AUTOSAR XML (schema 4-0-3)
package /ADPR_Code_pkg/ADPR_Code_swc
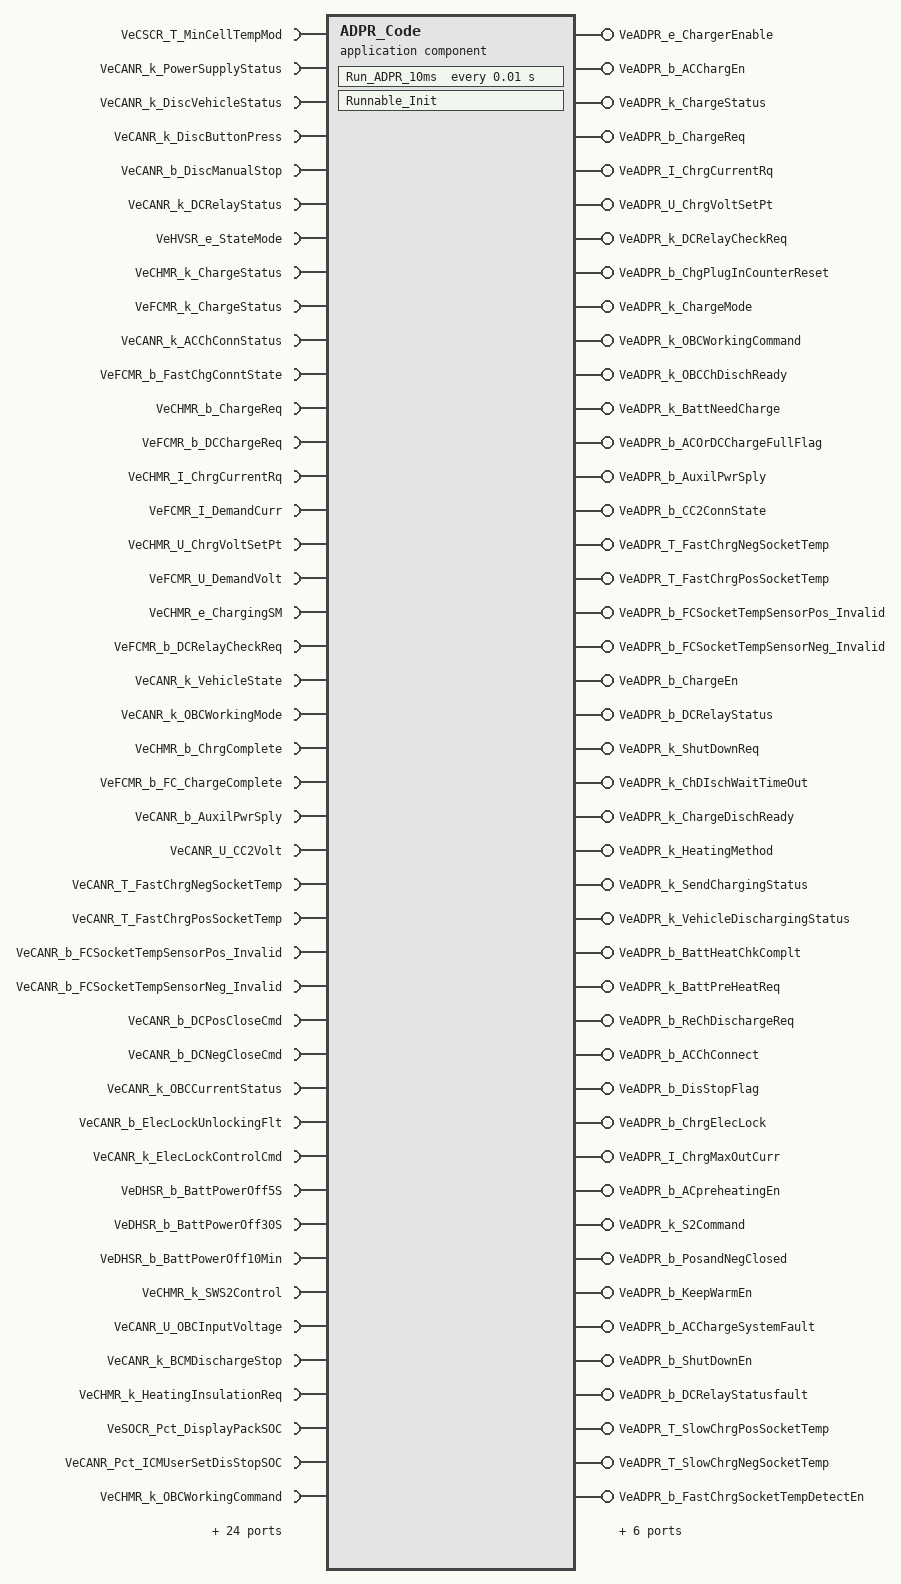
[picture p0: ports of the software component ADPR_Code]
  application sw component type ADPR_Code
    67 x require port:
      VeCSCR_T_MinCellTempMod: nonqueued-receiver-com-spec{data-element=VeCSCR_T_MinCellTempMod, init-value=0}, required-interface=VeCSCR_T_MinCellTempMod
      VeCANR_k_PowerSupplyStatus: nonqueued-receiver-com-spec{data-element=VeCANR_k_PowerSupplyStatus, init-value=0}, required-interface=VeCANR_k_PowerSupplyStatus
      VeCANR_k_DiscVehicleStatus: nonqueued-receiver-com-spec{data-element=VeCANR_k_DiscVehicleStatus, init-value=0}, required-interface=VeCANR_k_DiscVehicleStatus
      VeCANR_k_DiscButtonPress: nonqueued-receiver-com-spec{data-element=VeCANR_k_DiscButtonPress, init-value=0}, required-interface=VeCANR_k_DiscButtonPress
      VeCANR_b_DiscManualStop: nonqueued-receiver-com-spec{data-element=VeCANR_b_DiscManualStop, init-value=0}, required-interface=VeCANR_b_DiscManualStop
      VeCANR_k_DCRelayStatus: nonqueued-receiver-com-spec{data-element=VeCANR_k_DCRelayStatus, init-value=0}, required-interface=VeCANR_k_DCRelayStatus
      VeHVSR_e_StateMode: nonqueued-receiver-com-spec{data-element=VeHVSR_e_StateMode, init-value=CeHVSR_e_StateModeReserved}, required-interface=VeHVSR_e_StateMode
      VeCHMR_k_ChargeStatus: nonqueued-receiver-com-spec{data-element=VeCHMR_k_ChargeStatus, init-value=0}, required-interface=VeCHMR_k_ChargeStatus
      VeFCMR_k_ChargeStatus: nonqueued-receiver-com-spec{data-element=VeFCMR_k_ChargeStatus, init-value=0}, required-interface=VeFCMR_k_ChargeStatus
      VeCANR_k_ACChConnStatus: nonqueued-receiver-com-spec{data-element=VeCANR_k_ACChConnStatus, init-value=0}, required-interface=VeCANR_k_ACChConnStatus
      VeFCMR_b_FastChgConntState: nonqueued-receiver-com-spec{data-element=VeFCMR_b_FastChgConntState, init-value=0}, required-interface=VeFCMR_b_FastChgConntState
      VeCHMR_b_ChargeReq: nonqueued-receiver-com-spec{data-element=VeCHMR_b_ChargeReq, init-value=0}, required-interface=VeCHMR_b_ChargeReq
      VeFCMR_b_DCChargeReq: nonqueued-receiver-com-spec{data-element=VeFCMR_b_DCChargeReq, init-value=0}, required-interface=VeFCMR_b_DCChargeReq
      VeCHMR_I_ChrgCurrentRq: nonqueued-receiver-com-spec{data-element=VeCHMR_I_ChrgCurrentRq, init-value=0}, required-interface=VeCHMR_I_ChrgCurrentRq
      VeFCMR_I_DemandCurr: nonqueued-receiver-com-spec{data-element=VeFCMR_I_DemandCurr, init-value=0}, required-interface=VeFCMR_I_DemandCurr
      VeCHMR_U_ChrgVoltSetPt: nonqueued-receiver-com-spec{data-element=VeCHMR_U_ChrgVoltSetPt, init-value=0}, required-interface=VeCHMR_U_ChrgVoltSetPt
      VeFCMR_U_DemandVolt: nonqueued-receiver-com-spec{data-element=VeFCMR_U_DemandVolt, init-value=0}, required-interface=VeFCMR_U_DemandVolt
      VeCHMR_e_ChargingSM: nonqueued-receiver-com-spec{data-element=VeCHMR_e_ChargingSM, init-value=CeCHMR_e_ChargingSM_Off}, required-interface=VeCHMR_e_ChargingSM
      VeFCMR_b_DCRelayCheckReq: nonqueued-receiver-com-spec{data-element=VeFCMR_b_DCRelayCheckReq, init-value=0}, required-interface=VeFCMR_b_DCRelayCheckReq
      VeCANR_k_VehicleState: nonqueued-receiver-com-spec{data-element=VeCANR_k_VehicleState, init-value=0}, required-interface=VeCANR_k_VehicleState
      VeCANR_k_OBCWorkingMode: nonqueued-receiver-com-spec{data-element=VeCANR_k_OBCWorkingMode, init-value=0}, required-interface=VeCANR_k_OBCWorkingMode
      VeCHMR_b_ChrgComplete: nonqueued-receiver-com-spec{data-element=VeCHMR_b_ChrgComplete, init-value=0}, required-interface=VeCHMR_b_ChrgComplete
      VeFCMR_b_FC_ChargeComplete: nonqueued-receiver-com-spec{data-element=VeFCMR_b_FC_ChargeComplete, init-value=0}, required-interface=VeFCMR_b_FC_ChargeComplete
      VeCANR_b_AuxilPwrSply: nonqueued-receiver-com-spec{data-element=VeCANR_b_AuxilPwrSply, init-value=0}, required-interface=VeCANR_b_AuxilPwrSply
      VeCANR_U_CC2Volt: nonqueued-receiver-com-spec{data-element=VeCANR_U_CC2Volt, init-value=0}, required-interface=VeCANR_U_CC2Volt
      VeCANR_T_FastChrgNegSocketTemp: nonqueued-receiver-com-spec{data-element=VeCANR_T_FastChrgNegSocketTemp, init-value=0}, required-interface=VeCANR_T_FastChrgNegSocketTemp
      VeCANR_T_FastChrgPosSocketTemp: nonqueued-receiver-com-spec{data-element=VeCANR_T_FastChrgPosSocketTemp, init-value=0}, required-interface=VeCANR_T_FastChrgPosSocketTemp
      VeCANR_b_FCSocketTempSensorPos_Invalid: nonqueued-receiver-com-spec{data-element=VeCANR_b_FCSocketTempSensorPos_Invalid, init-value=0}, required-interface=VeCANR_b_FCSocketTempSensorPos_Invalid
      VeCANR_b_FCSocketTempSensorNeg_Invalid: nonqueued-receiver-com-spec{data-element=VeCANR_b_FCSocketTempSensorNeg_Invalid, init-value=0}, required-interface=VeCANR_b_FCSocketTempSensorNeg_Invalid
      VeCANR_b_DCPosCloseCmd: nonqueued-receiver-com-spec{data-element=VeCANR_b_DCPosCloseCmd, init-value=0}, required-interface=VeCANR_b_DCPosCloseCmd
      VeCANR_b_DCNegCloseCmd: nonqueued-receiver-com-spec{data-element=VeCANR_b_DCNegCloseCmd, init-value=0}, required-interface=VeCANR_b_DCNegCloseCmd
      VeCANR_k_OBCCurrentStatus: nonqueued-receiver-com-spec{data-element=VeCANR_k_OBCCurrentStatus, init-value=0}, required-interface=VeCANR_k_OBCCurrentStatus
      VeCANR_b_ElecLockUnlockingFlt: nonqueued-receiver-com-spec{data-element=VeCANR_b_ElecLockUnlockingFlt, init-value=0}, required-interface=VeCANR_b_ElecLockUnlockingFlt
      VeCANR_k_ElecLockControlCmd: nonqueued-receiver-com-spec{data-element=VeCANR_k_ElecLockControlCmd, init-value=0}, required-interface=VeCANR_k_ElecLockControlCmd
      VeDHSR_b_BattPowerOff5S: nonqueued-receiver-com-spec{data-element=VeDHSR_b_BattPowerOff5S, init-value=0}, required-interface=VeDHSR_b_BattPowerOff5S
      VeDHSR_b_BattPowerOff30S: nonqueued-receiver-com-spec{data-element=VeDHSR_b_BattPowerOff30S, init-value=0}, required-interface=VeDHSR_b_BattPowerOff30S
      VeDHSR_b_BattPowerOff10Min: nonqueued-receiver-com-spec{data-element=VeDHSR_b_BattPowerOff10Min, init-value=0}, required-interface=VeDHSR_b_BattPowerOff10Min
      VeCHMR_k_SWS2Control: nonqueued-receiver-com-spec{data-element=VeCHMR_k_SWS2Control, init-value=0}, required-interface=VeCHMR_k_SWS2Control
      VeCANR_U_OBCInputVoltage: nonqueued-receiver-com-spec{data-element=VeCANR_U_OBCInputVoltage, init-value=0}, required-interface=VeCANR_U_OBCInputVoltage
      VeCANR_k_BCMDischargeStop: nonqueued-receiver-com-spec{data-element=VeCANR_k_BCMDischargeStop, init-value=0}, required-interface=VeCANR_k_BCMDischargeStop
      VeCHMR_k_HeatingInsulationReq: nonqueued-receiver-com-spec{data-element=VeCHMR_k_HeatingInsulationReq, init-value=0}, required-interface=VeCHMR_k_HeatingInsulationReq
      VeSOCR_Pct_DisplayPackSOC: nonqueued-receiver-com-spec{data-element=VeSOCR_Pct_DisplayPackSOC, init-value=0}, required-interface=VeSOCR_Pct_DisplayPackSOC
      VeCANR_Pct_ICMUserSetDisStopSOC: nonqueued-receiver-com-spec{data-element=VeCANR_Pct_ICMUserSetDisStopSOC, init-value=0}, required-interface=VeCANR_Pct_ICMUserSetDisStopSOC
      VeCHMR_k_OBCWorkingCommand: nonqueued-receiver-com-spec{data-element=VeCHMR_k_OBCWorkingCommand, init-value=0}, required-interface=VeCHMR_k_OBCWorkingCommand
      VeCANR_k_VCUVehicleModel: nonqueued-receiver-com-spec{data-element=VeCANR_k_VCUVehicleModel, init-value=0}, required-interface=VeCANR_k_VCUVehicleModel
      VeCHMR_b_HeatingInsulationReqcomplt: nonqueued-receiver-com-spec{data-element=VeCHMR_b_HeatingInsulationReqcomplt, init-value=0}, required-interface=VeCHMR_b_HeatingInsulationReqcomplt
      VeFCMR_b_DCPreHeatChkCmplt: nonqueued-receiver-com-spec{data-element=VeFCMR_b_DCPreHeatChkCmplt, init-value=0}, required-interface=VeFCMR_b_DCPreHeatChkCmplt
      VeFCMR_b_DCPreHeatReq: nonqueued-receiver-com-spec{data-element=VeFCMR_b_DCPreHeatReq, init-value=0}, required-interface=VeFCMR_b_DCPreHeatReq
      VeCHMR_b_ReChargeStatus: nonqueued-receiver-com-spec{data-element=VeCHMR_b_ReChargeStatus, init-value=0}, required-interface=VeCHMR_b_ReChargeStatus
      VeCANR_b_ACAwake: nonqueued-receiver-com-spec{data-element=VeCANR_b_ACAwake, init-value=0}, required-interface=VeCANR_b_ACAwake
      VeCANR_e_ChrgElecLock: nonqueued-receiver-com-spec{data-element=VeCANR_e_ChrgElecLock, init-value=CeCHMR_e_ChrgElecLockUnlock}, required-interface=VeCANR_e_ChrgElecLock
      VeCSCR_U_PackVoltage_out: nonqueued-receiver-com-spec{data-element=VeCSCR_U_PackVoltage_out, init-value=0}, required-interface=VeCSCR_U_PackVoltage_out
      VeFCMR_b_DC_PowerDownReq: nonqueued-receiver-com-spec{data-element=VeFCMR_b_DC_PowerDownReq, init-value=0}, required-interface=VeFCMR_b_DC_PowerDownReq
      VeFCMR_e_ChrgOffBoardSt: nonqueued-receiver-com-spec{data-element=VeFCMR_e_ChrgOffBoardSt, init-value=CeFCMR_e_ChrgOffBoard_Init}, required-interface=VeFCMR_e_ChrgOffBoardSt
      VeCANR_b_OnWakeUp: nonqueued-receiver-com-spec{data-element=VeCANR_b_OnWakeUp, init-value=0}, required-interface=VeCANR_b_OnWakeUp
      VeCANR_b_GridBreakeFlag: nonqueued-receiver-com-spec{data-element=VeCANR_b_GridBreakeFlag, init-value=0}, required-interface=VeCANR_b_GridBreakeFlag
      VeFCMR_k_KeepWarmReqStatus: nonqueued-receiver-com-spec{data-element=VeFCMR_k_KeepWarmReqStatus, init-value=0}, required-interface=VeFCMR_k_KeepWarmReqStatus
      VeTHMR_k_BMSToEHUInslationReq: nonqueued-receiver-com-spec{data-element=VeTHMR_k_BMSToEHUInslationReq, init-value=0}, required-interface=VeTHMR_k_BMSToEHUInslationReq
      VeDHSR_b_ChargeStandby: nonqueued-receiver-com-spec{data-element=VeDHSR_b_ChargeStandby, init-value=0}, required-interface=VeDHSR_b_ChargeStandby
      VeDHSR_b_ChargeReqPOff: nonqueued-receiver-com-spec{data-element=VeDHSR_b_ChargeReqPOff, init-value=0}, required-interface=VeDHSR_b_ChargeReqPOff
      VeCANR_b_ECCFucLimitCMD: nonqueued-receiver-com-spec{data-element=VeCANR_b_ECCFucLimitCMD, init-value=0}, required-interface=VeCANR_b_ECCFucLimitCMD
      VeCFLR_b_HeatContactor: nonqueued-receiver-com-spec{data-element=VeCFLR_b_HeatContactor, init-value=0}, required-interface=VeCFLR_b_HeatContactor
      VeCHMR_b_ActiveHeatFlag: nonqueued-receiver-com-spec{data-element=VeCHMR_b_ActiveHeatFlag, init-value=0}, required-interface=VeCHMR_b_ActiveHeatFlag
      VeCANR_Pct_CPDutyVl: nonqueued-receiver-com-spec{data-element=VeCANR_Pct_CPDutyVl, init-value=0}, required-interface=VeCANR_Pct_CPDutyVl
      VeCANR_b_CPDutyFault: nonqueued-receiver-com-spec{data-element=VeCANR_b_CPDutyFault, init-value=0}, required-interface=VeCANR_b_CPDutyFault
      VeCHMR_b_HeatReset: nonqueued-receiver-com-spec{data-element=VeCHMR_b_HeatReset, init-value=0}, required-interface=VeCHMR_b_HeatReset
      VeLLSR_k_ActiveVariant: nonqueued-receiver-com-spec{data-element=VeLLSR_k_ActiveVariant, init-value=0}, required-interface=VeLLSR_k_ActiveVariant
    50 x provide port:
      VeADPR_e_ChargerEnable: nonqueued-sender-com-spec{data-element=VeADPR_e_ChargerEnable, init-value=CeCHMR_e_OBC_ChrgEnblDefault}, provided-interface=VeADPR_e_ChargerEnable
      VeADPR_b_ACChargEn: nonqueued-sender-com-spec{data-element=VeADPR_b_ACChargEn, init-value=0}, provided-interface=VeADPR_b_ACChargEn
      VeADPR_k_ChargeStatus: nonqueued-sender-com-spec{data-element=VeADPR_k_ChargeStatus, init-value=0}, provided-interface=VeADPR_k_ChargeStatus
      VeADPR_b_ChargeReq: nonqueued-sender-com-spec{data-element=VeADPR_b_ChargeReq, init-value=0}, provided-interface=VeADPR_b_ChargeReq
      VeADPR_I_ChrgCurrentRq: nonqueued-sender-com-spec{data-element=VeADPR_I_ChrgCurrentRq, init-value=0}, provided-interface=VeADPR_I_ChrgCurrentRq
      VeADPR_U_ChrgVoltSetPt: nonqueued-sender-com-spec{data-element=VeADPR_U_ChrgVoltSetPt, init-value=0}, provided-interface=VeADPR_U_ChrgVoltSetPt
      VeADPR_k_DCRelayCheckReq: nonqueued-sender-com-spec{data-element=VeADPR_k_DCRelayCheckReq, init-value=0}, provided-interface=VeADPR_k_DCRelayCheckReq
      VeADPR_b_ChgPlugInCounterReset: nonqueued-sender-com-spec{data-element=VeADPR_b_ChgPlugInCounterReset, init-value=0}, provided-interface=VeADPR_b_ChgPlugInCounterReset
      VeADPR_k_ChargeMode: nonqueued-sender-com-spec{data-element=VeADPR_k_ChargeMode, init-value=0}, provided-interface=VeADPR_k_ChargeMode
      VeADPR_k_OBCWorkingCommand: nonqueued-sender-com-spec{data-element=VeADPR_k_OBCWorkingCommand, init-value=0}, provided-interface=VeADPR_k_OBCWorkingCommand
      VeADPR_k_OBCChDischReady: nonqueued-sender-com-spec{data-element=VeADPR_k_OBCChDischReady, init-value=0}, provided-interface=VeADPR_k_OBCChDischReady
      VeADPR_k_BattNeedCharge: nonqueued-sender-com-spec{data-element=VeADPR_k_BattNeedCharge, init-value=0}, provided-interface=VeADPR_k_BattNeedCharge
      VeADPR_b_ACOrDCChargeFullFlag: nonqueued-sender-com-spec{data-element=VeADPR_b_ACOrDCChargeFullFlag, init-value=0}, provided-interface=VeADPR_b_ACOrDCChargeFullFlag
      VeADPR_b_AuxilPwrSply: nonqueued-sender-com-spec{data-element=VeADPR_b_AuxilPwrSply, init-value=0}, provided-interface=VeADPR_b_AuxilPwrSply
      VeADPR_b_CC2ConnState: nonqueued-sender-com-spec{data-element=VeADPR_b_CC2ConnState, init-value=0}, provided-interface=VeADPR_b_CC2ConnState
      VeADPR_T_FastChrgNegSocketTemp: nonqueued-sender-com-spec{data-element=VeADPR_T_FastChrgNegSocketTemp, init-value=0}, provided-interface=VeADPR_T_FastChrgNegSocketTemp
      VeADPR_T_FastChrgPosSocketTemp: nonqueued-sender-com-spec{data-element=VeADPR_T_FastChrgPosSocketTemp, init-value=0}, provided-interface=VeADPR_T_FastChrgPosSocketTemp
      VeADPR_b_FCSocketTempSensorPos_Invalid: nonqueued-sender-com-spec{data-element=VeADPR_b_FCSocketTempSensorPos_Invalid, init-value=0}, provided-interface=VeADPR_b_FCSocketTempSensorPos_Invalid
      VeADPR_b_FCSocketTempSensorNeg_Invalid: nonqueued-sender-com-spec{data-element=VeADPR_b_FCSocketTempSensorNeg_Invalid, init-value=0}, provided-interface=VeADPR_b_FCSocketTempSensorNeg_Invalid
      VeADPR_b_ChargeEn: nonqueued-sender-com-spec{data-element=VeADPR_b_ChargeEn, init-value=0}, provided-interface=VeADPR_b_ChargeEn
      VeADPR_b_DCRelayStatus: nonqueued-sender-com-spec{data-element=VeADPR_b_DCRelayStatus, init-value=0}, provided-interface=VeADPR_b_DCRelayStatus
      VeADPR_k_ShutDownReq: nonqueued-sender-com-spec{data-element=VeADPR_k_ShutDownReq, init-value=0}, provided-interface=VeADPR_k_ShutDownReq
      VeADPR_k_ChDIschWaitTimeOut: nonqueued-sender-com-spec{data-element=VeADPR_k_ChDIschWaitTimeOut, init-value=0}, provided-interface=VeADPR_k_ChDIschWaitTimeOut
      VeADPR_k_ChargeDischReady: nonqueued-sender-com-spec{data-element=VeADPR_k_ChargeDischReady, init-value=0}, provided-interface=VeADPR_k_ChargeDischReady
      VeADPR_k_HeatingMethod: nonqueued-sender-com-spec{data-element=VeADPR_k_HeatingMethod, init-value=0}, provided-interface=VeADPR_k_HeatingMethod
      VeADPR_k_SendChargingStatus: nonqueued-sender-com-spec{data-element=VeADPR_k_SendChargingStatus, init-value=0}, provided-interface=VeADPR_k_SendChargingStatus
      VeADPR_k_VehicleDischargingStatus: nonqueued-sender-com-spec{data-element=VeADPR_k_VehicleDischargingStatus, init-value=0}, provided-interface=VeADPR_k_VehicleDischargingStatus
      VeADPR_b_BattHeatChkComplt: nonqueued-sender-com-spec{data-element=VeADPR_b_BattHeatChkComplt, init-value=0}, provided-interface=VeADPR_b_BattHeatChkComplt
      VeADPR_k_BattPreHeatReq: nonqueued-sender-com-spec{data-element=VeADPR_k_BattPreHeatReq, init-value=0}, provided-interface=VeADPR_k_BattPreHeatReq
      VeADPR_b_ReChDischargeReq: nonqueued-sender-com-spec{data-element=VeADPR_b_ReChDischargeReq, init-value=0}, provided-interface=VeADPR_b_ReChDischargeReq
      VeADPR_b_ACChConnect: nonqueued-sender-com-spec{data-element=VeADPR_b_ACChConnect, init-value=0}, provided-interface=VeADPR_b_ACChConnect
      VeADPR_b_DisStopFlag: nonqueued-sender-com-spec{data-element=VeADPR_b_DisStopFlag, init-value=0}, provided-interface=VeADPR_b_DisStopFlag
      VeADPR_b_ChrgElecLock: nonqueued-sender-com-spec{data-element=VeADPR_b_ChrgElecLock, init-value=0}, provided-interface=VeADPR_b_ChrgElecLock
      VeADPR_I_ChrgMaxOutCurr: nonqueued-sender-com-spec{data-element=VeADPR_I_ChrgMaxOutCurr, init-value=0}, provided-interface=VeADPR_I_ChrgMaxOutCurr
      VeADPR_b_ACpreheatingEn: nonqueued-sender-com-spec{data-element=VeADPR_b_ACpreheatingEn, init-value=0}, provided-interface=VeADPR_b_ACpreheatingEn
      VeADPR_k_S2Command: nonqueued-sender-com-spec{data-element=VeADPR_k_S2Command, init-value=0}, provided-interface=VeADPR_k_S2Command
      VeADPR_b_PosandNegClosed: nonqueued-sender-com-spec{data-element=VeADPR_b_PosandNegClosed, init-value=0}, provided-interface=VeADPR_b_PosandNegClosed
      VeADPR_b_KeepWarmEn: nonqueued-sender-com-spec{data-element=VeADPR_b_KeepWarmEn, init-value=0}, provided-interface=VeADPR_b_KeepWarmEn
      VeADPR_b_ACChargeSystemFault: nonqueued-sender-com-spec{data-element=VeADPR_b_ACChargeSystemFault, init-value=0}, provided-interface=VeADPR_b_ACChargeSystemFault
      VeADPR_b_ShutDownEn: nonqueued-sender-com-spec{data-element=VeADPR_b_ShutDownEn, init-value=0}, provided-interface=VeADPR_b_ShutDownEn
      VeADPR_b_DCRelayStatusfault: nonqueued-sender-com-spec{data-element=VeADPR_b_DCRelayStatusfault, init-value=0}, provided-interface=VeADPR_b_DCRelayStatusfault
      VeADPR_T_SlowChrgPosSocketTemp: nonqueued-sender-com-spec{data-element=VeADPR_T_SlowChrgPosSocketTemp, init-value=0}, provided-interface=VeADPR_T_SlowChrgPosSocketTemp
      VeADPR_T_SlowChrgNegSocketTemp: nonqueued-sender-com-spec{data-element=VeADPR_T_SlowChrgNegSocketTemp, init-value=0}, provided-interface=VeADPR_T_SlowChrgNegSocketTemp
      VeADPR_b_FastChrgSocketTempDetectEn: nonqueued-sender-com-spec{data-element=VeADPR_b_FastChrgSocketTempDetectEn, init-value=0}, provided-interface=VeADPR_b_FastChrgSocketTempDetectEn
      VeADPR_b_ECCFucLimitCMD: nonqueued-sender-com-spec{data-element=VeADPR_b_ECCFucLimitCMD, init-value=0}, provided-interface=VeADPR_b_ECCFucLimitCMD
      VeADPR_k_BookSetReq: nonqueued-sender-com-spec{data-element=VeADPR_k_BookSetReq, init-value=0}, provided-interface=VeADPR_k_BookSetReq
      VeADPR_k_IntelligentChargeReq: nonqueued-sender-com-spec{data-element=VeADPR_k_IntelligentChargeReq, init-value=0}, provided-interface=VeADPR_k_IntelligentChargeReq
      VeADPR_k_BatteryMaintainLightReq: nonqueued-sender-com-spec{data-element=VeADPR_k_BatteryMaintainLightReq, init-value=0}, provided-interface=VeADPR_k_BatteryMaintainLightReq
      VeADPR_k_ChargeOutMinCurSet: nonqueued-sender-com-spec{data-element=VeADPR_k_ChargeOutMinCurSet, init-value=0}, provided-interface=VeADPR_k_ChargeOutMinCurSet
      VeADPR_b_ACPConnect: nonqueued-sender-com-spec{data-element=VeADPR_b_ACPConnect, init-value=0}, provided-interface=VeADPR_b_ACPConnect
    require port ADPR_Rport: required-interface=ADPR_if
    behavior ADPR_Code: data-type-mapping=ADPR_CodeDataTypeMappingsSet, handle-termination-and-restart=NO-SUPPORT
      constant-memorys:
        parameter data prototype CtADPR_kP_SOC_TempAChrgPwrLmt: category=COM_AXIS, sw-calibration-access=READ-WRITE, type=Appl_CtADPR_kP_SOC_TempAChrgPwrLmt, init-value=constant-reference={short-label=CtADPR_kP_SOC_TempAChrgPwrLmt, constant=CtADPR_kP_SOC_TempAChrgPwrLmt}
        parameter data prototype CxADPR_kP_SOC_TempAChrgPwrLmt: category=COM_AXIS, sw-calibration-access=READ-WRITE, type=Appl_CxADPR_kP_SOC_TempAChrgPwrLmt, init-value=constant-reference={short-label=CxADPR_kP_SOC_TempAChrgPwrLmt, constant=CxADPR_kP_SOC_TempAChrgPwrLmt}
        parameter data prototype CzADPR_kP_SOC_TempAChrgPwrLmt_data: category=MAP, sw-calibration-access=READ-WRITE, type=Appl_CzADPR_kP_SOC_TempAChrgPwrLmt_data, init-value=constant-reference={short-label=CzADPR_kP_SOC_TempAChrgPwrLmt_data, constant=CzADPR_kP_SOC_TempAChrgPwrLmt_data}
      timing event Event_Run_ADPR_10ms: start-on-event=Run_ADPR_10ms, period=0.01
      runnable Runnable_Init: symbol=ADPR_Code_Init
        data-send-points:
          5 x access:
            OUT_VeADPR_k_BatteryMaintainLightReq_VeADPR_k_fe70eb47f5ac9770: accessed-variable=VeADPR_k_BatteryMaintainLightReq.VeADPR_k_BatteryMaintainLightReq
            OUT_VeADPR_k_BookSetReq_VeADPR_k_BookSetReq: accessed-variable=VeADPR_k_BookSetReq.VeADPR_k_BookSetReq
            OUT_VeADPR_k_ChargeOutMinCurSet_VeADPR_k_ChargeOutMinCurSet: accessed-variable=VeADPR_k_ChargeOutMinCurSet.VeADPR_k_ChargeOutMinCurSet
            OUT_VeADPR_k_IntelligentChargeReq_VeADPR_k_In_7bfd18d47cf846ba: accessed-variable=VeADPR_k_IntelligentChargeReq.VeADPR_k_IntelligentChargeReq
            OUT_VeADPR_k_OBCWorkingCommand_VeADPR_k_OBCWorkingCommand: accessed-variable=VeADPR_k_OBCWorkingCommand.VeADPR_k_OBCWorkingCommand
      runnable Run_ADPR_10ms
        data-read-access:
          67 x access:
            IN_VeCANR_Pct_CPDutyVl_VeCANR_Pct_CPDutyVl: accessed-variable=VeCANR_Pct_CPDutyVl.VeCANR_Pct_CPDutyVl
            IN_VeCANR_Pct_ICMUserSetDisStopSOC_VeCANR_Pct_aab78b47d5180290: accessed-variable=VeCANR_Pct_ICMUserSetDisStopSOC.VeCANR_Pct_ICMUserSetDisStopSOC
            IN_VeCANR_T_FastChrgNegSocketTemp_VeCANR_T_Fa_f013e12589865141: accessed-variable=VeCANR_T_FastChrgNegSocketTemp.VeCANR_T_FastChrgNegSocketTemp
            IN_VeCANR_T_FastChrgPosSocketTemp_VeCANR_T_Fa_e1def13a944f9df5: accessed-variable=VeCANR_T_FastChrgPosSocketTemp.VeCANR_T_FastChrgPosSocketTemp
            IN_VeCANR_U_CC2Volt_VeCANR_U_CC2Volt: accessed-variable=VeCANR_U_CC2Volt.VeCANR_U_CC2Volt
            IN_VeCANR_U_OBCInputVoltage_VeCANR_U_OBCInputVoltage: accessed-variable=VeCANR_U_OBCInputVoltage.VeCANR_U_OBCInputVoltage
            IN_VeCANR_b_ACAwake_VeCANR_b_ACAwake: accessed-variable=VeCANR_b_ACAwake.VeCANR_b_ACAwake
            IN_VeCANR_b_AuxilPwrSply_VeCANR_b_AuxilPwrSply: accessed-variable=VeCANR_b_AuxilPwrSply.VeCANR_b_AuxilPwrSply
            IN_VeCANR_b_CPDutyFault_VeCANR_b_CPDutyFault: accessed-variable=VeCANR_b_CPDutyFault.VeCANR_b_CPDutyFault
            IN_VeCANR_b_DCNegCloseCmd_VeCANR_b_DCNegCloseCmd: accessed-variable=VeCANR_b_DCNegCloseCmd.VeCANR_b_DCNegCloseCmd
            IN_VeCANR_b_DCPosCloseCmd_VeCANR_b_DCPosCloseCmd: accessed-variable=VeCANR_b_DCPosCloseCmd.VeCANR_b_DCPosCloseCmd
            IN_VeCANR_b_DiscManualStop_VeCANR_b_DiscManualStop: accessed-variable=VeCANR_b_DiscManualStop.VeCANR_b_DiscManualStop
            IN_VeCANR_b_ECCFucLimitCMD_VeCANR_b_ECCFucLimitCMD: accessed-variable=VeCANR_b_ECCFucLimitCMD.VeCANR_b_ECCFucLimitCMD
            IN_VeCANR_b_ElecLockUnlockingFlt_VeCANR_b_ElecLockUnlockingFlt: accessed-variable=VeCANR_b_ElecLockUnlockingFlt.VeCANR_b_ElecLockUnlockingFlt
            IN_VeCANR_b_FCSocketTempSensorNeg_Invalid_VeC_bd8a7fb2a42e4b4f: accessed-variable=VeCANR_b_FCSocketTempSensorNeg_Invalid.VeCANR_b_FCSocketTempSensorNeg_Invalid
            IN_VeCANR_b_FCSocketTempSensorPos_Invalid_VeC_506049b2fd37971b: accessed-variable=VeCANR_b_FCSocketTempSensorPos_Invalid.VeCANR_b_FCSocketTempSensorPos_Invalid
            IN_VeCANR_b_GridBreakeFlag_VeCANR_b_GridBreakeFlag: accessed-variable=VeCANR_b_GridBreakeFlag.VeCANR_b_GridBreakeFlag
            IN_VeCANR_b_OnWakeUp_VeCANR_b_OnWakeUp: accessed-variable=VeCANR_b_OnWakeUp.VeCANR_b_OnWakeUp
            IN_VeCANR_e_ChrgElecLock_VeCANR_e_ChrgElecLock: accessed-variable=VeCANR_e_ChrgElecLock.VeCANR_e_ChrgElecLock
            IN_VeCANR_k_ACChConnStatus_VeCANR_k_ACChConnStatus: accessed-variable=VeCANR_k_ACChConnStatus.VeCANR_k_ACChConnStatus
            IN_VeCANR_k_BCMDischargeStop_VeCANR_k_BCMDischargeStop: accessed-variable=VeCANR_k_BCMDischargeStop.VeCANR_k_BCMDischargeStop
            IN_VeCANR_k_DCRelayStatus_VeCANR_k_DCRelayStatus: accessed-variable=VeCANR_k_DCRelayStatus.VeCANR_k_DCRelayStatus
            IN_VeCANR_k_DiscButtonPress_VeCANR_k_DiscButtonPress: accessed-variable=VeCANR_k_DiscButtonPress.VeCANR_k_DiscButtonPress
            IN_VeCANR_k_DiscVehicleStatus_VeCANR_k_DiscVehicleStatus: accessed-variable=VeCANR_k_DiscVehicleStatus.VeCANR_k_DiscVehicleStatus
            IN_VeCANR_k_ElecLockControlCmd_VeCANR_k_ElecLockControlCmd: accessed-variable=VeCANR_k_ElecLockControlCmd.VeCANR_k_ElecLockControlCmd
            IN_VeCANR_k_OBCCurrentStatus_VeCANR_k_OBCCurrentStatus: accessed-variable=VeCANR_k_OBCCurrentStatus.VeCANR_k_OBCCurrentStatus
            IN_VeCANR_k_OBCWorkingMode_VeCANR_k_OBCWorkingMode: accessed-variable=VeCANR_k_OBCWorkingMode.VeCANR_k_OBCWorkingMode
            IN_VeCANR_k_PowerSupplyStatus_VeCANR_k_PowerSupplyStatus: accessed-variable=VeCANR_k_PowerSupplyStatus.VeCANR_k_PowerSupplyStatus
            IN_VeCANR_k_VCUVehicleModel_VeCANR_k_VCUVehicleModel: accessed-variable=VeCANR_k_VCUVehicleModel.VeCANR_k_VCUVehicleModel
            IN_VeCANR_k_VehicleState_VeCANR_k_VehicleState: accessed-variable=VeCANR_k_VehicleState.VeCANR_k_VehicleState
            IN_VeCFLR_b_HeatContactor_VeCFLR_b_HeatContactor: accessed-variable=VeCFLR_b_HeatContactor.VeCFLR_b_HeatContactor
            IN_VeCHMR_I_ChrgCurrentRq_VeCHMR_I_ChrgCurrentRq: accessed-variable=VeCHMR_I_ChrgCurrentRq.VeCHMR_I_ChrgCurrentRq
            IN_VeCHMR_U_ChrgVoltSetPt_VeCHMR_U_ChrgVoltSetPt: accessed-variable=VeCHMR_U_ChrgVoltSetPt.VeCHMR_U_ChrgVoltSetPt
            IN_VeCHMR_b_ActiveHeatFlag_VeCHMR_b_ActiveHeatFlag: accessed-variable=VeCHMR_b_ActiveHeatFlag.VeCHMR_b_ActiveHeatFlag
            IN_VeCHMR_b_ChargeReq_VeCHMR_b_ChargeReq: accessed-variable=VeCHMR_b_ChargeReq.VeCHMR_b_ChargeReq
            IN_VeCHMR_b_ChrgComplete_VeCHMR_b_ChrgComplete: accessed-variable=VeCHMR_b_ChrgComplete.VeCHMR_b_ChrgComplete
            IN_VeCHMR_b_HeatReset_VeCHMR_b_HeatReset: accessed-variable=VeCHMR_b_HeatReset.VeCHMR_b_HeatReset
            IN_VeCHMR_b_HeatingInsulationReqcomplt_VeCHMR_a2e7b37113afb418: accessed-variable=VeCHMR_b_HeatingInsulationReqcomplt.VeCHMR_b_HeatingInsulationReqcomplt
            IN_VeCHMR_b_ReChargeStatus_VeCHMR_b_ReChargeStatus: accessed-variable=VeCHMR_b_ReChargeStatus.VeCHMR_b_ReChargeStatus
            IN_VeCHMR_e_ChargingSM_VeCHMR_e_ChargingSM: accessed-variable=VeCHMR_e_ChargingSM.VeCHMR_e_ChargingSM
            IN_VeCHMR_k_ChargeStatus_VeCHMR_k_ChargeStatus: accessed-variable=VeCHMR_k_ChargeStatus.VeCHMR_k_ChargeStatus
            IN_VeCHMR_k_HeatingInsulationReq_VeCHMR_k_HeatingInsulationReq: accessed-variable=VeCHMR_k_HeatingInsulationReq.VeCHMR_k_HeatingInsulationReq
            IN_VeCHMR_k_OBCWorkingCommand_VeCHMR_k_OBCWorkingCommand: accessed-variable=VeCHMR_k_OBCWorkingCommand.VeCHMR_k_OBCWorkingCommand
            IN_VeCHMR_k_SWS2Control_VeCHMR_k_SWS2Control: accessed-variable=VeCHMR_k_SWS2Control.VeCHMR_k_SWS2Control
            IN_VeCSCR_T_MinCellTempMod_VeCSCR_T_MinCellTempMod: accessed-variable=VeCSCR_T_MinCellTempMod.VeCSCR_T_MinCellTempMod
            IN_VeCSCR_U_PackVoltage_out_VeCSCR_U_PackVoltage_out: accessed-variable=VeCSCR_U_PackVoltage_out.VeCSCR_U_PackVoltage_out
            IN_VeDHSR_b_BattPowerOff10Min_VeDHSR_b_BattPowerOff10Min: accessed-variable=VeDHSR_b_BattPowerOff10Min.VeDHSR_b_BattPowerOff10Min
            IN_VeDHSR_b_BattPowerOff30S_VeDHSR_b_BattPowerOff30S: accessed-variable=VeDHSR_b_BattPowerOff30S.VeDHSR_b_BattPowerOff30S
            IN_VeDHSR_b_BattPowerOff5S_VeDHSR_b_BattPowerOff5S: accessed-variable=VeDHSR_b_BattPowerOff5S.VeDHSR_b_BattPowerOff5S
            IN_VeDHSR_b_ChargeReqPOff_VeDHSR_b_ChargeReqPOff: accessed-variable=VeDHSR_b_ChargeReqPOff.VeDHSR_b_ChargeReqPOff
            IN_VeDHSR_b_ChargeStandby_VeDHSR_b_ChargeStandby: accessed-variable=VeDHSR_b_ChargeStandby.VeDHSR_b_ChargeStandby
            IN_VeFCMR_I_DemandCurr_VeFCMR_I_DemandCurr: accessed-variable=VeFCMR_I_DemandCurr.VeFCMR_I_DemandCurr
            IN_VeFCMR_U_DemandVolt_VeFCMR_U_DemandVolt: accessed-variable=VeFCMR_U_DemandVolt.VeFCMR_U_DemandVolt
            IN_VeFCMR_b_DCChargeReq_VeFCMR_b_DCChargeReq: accessed-variable=VeFCMR_b_DCChargeReq.VeFCMR_b_DCChargeReq
            IN_VeFCMR_b_DCPreHeatChkCmplt_VeFCMR_b_DCPreHeatChkCmplt: accessed-variable=VeFCMR_b_DCPreHeatChkCmplt.VeFCMR_b_DCPreHeatChkCmplt
            IN_VeFCMR_b_DCPreHeatReq_VeFCMR_b_DCPreHeatReq: accessed-variable=VeFCMR_b_DCPreHeatReq.VeFCMR_b_DCPreHeatReq
            IN_VeFCMR_b_DCRelayCheckReq_VeFCMR_b_DCRelayCheckReq: accessed-variable=VeFCMR_b_DCRelayCheckReq.VeFCMR_b_DCRelayCheckReq
            IN_VeFCMR_b_DC_PowerDownReq_VeFCMR_b_DC_PowerDownReq: accessed-variable=VeFCMR_b_DC_PowerDownReq.VeFCMR_b_DC_PowerDownReq
            IN_VeFCMR_b_FC_ChargeComplete_VeFCMR_b_FC_ChargeComplete: accessed-variable=VeFCMR_b_FC_ChargeComplete.VeFCMR_b_FC_ChargeComplete
            IN_VeFCMR_b_FastChgConntState_VeFCMR_b_FastChgConntState: accessed-variable=VeFCMR_b_FastChgConntState.VeFCMR_b_FastChgConntState
            IN_VeFCMR_e_ChrgOffBoardSt_VeFCMR_e_ChrgOffBoardSt: accessed-variable=VeFCMR_e_ChrgOffBoardSt.VeFCMR_e_ChrgOffBoardSt
            IN_VeFCMR_k_ChargeStatus_VeFCMR_k_ChargeStatus: accessed-variable=VeFCMR_k_ChargeStatus.VeFCMR_k_ChargeStatus
            IN_VeFCMR_k_KeepWarmReqStatus_VeFCMR_k_KeepWarmReqStatus: accessed-variable=VeFCMR_k_KeepWarmReqStatus.VeFCMR_k_KeepWarmReqStatus
            IN_VeHVSR_e_StateMode_VeHVSR_e_StateMode: accessed-variable=VeHVSR_e_StateMode.VeHVSR_e_StateMode
            IN_VeLLSR_k_ActiveVariant_VeLLSR_k_ActiveVariant: accessed-variable=VeLLSR_k_ActiveVariant.VeLLSR_k_ActiveVariant
            IN_VeSOCR_Pct_DisplayPackSOC_VeSOCR_Pct_DisplayPackSOC: accessed-variable=VeSOCR_Pct_DisplayPackSOC.VeSOCR_Pct_DisplayPackSOC
            IN_VeTHMR_k_BMSToEHUInslationReq_VeTHMR_k_BMSToEHUInslationReq: accessed-variable=VeTHMR_k_BMSToEHUInslationReq.VeTHMR_k_BMSToEHUInslationReq
        data-send-points:
          50 x access:
            OUT_VeADPR_e_ChargerEnable_VeADPR_e_ChargerEnable: accessed-variable=VeADPR_e_ChargerEnable.VeADPR_e_ChargerEnable
            OUT_VeADPR_b_ACChargEn_VeADPR_b_ACChargEn: accessed-variable=VeADPR_b_ACChargEn.VeADPR_b_ACChargEn
            OUT_VeADPR_k_ChargeStatus_VeADPR_k_ChargeStatus: accessed-variable=VeADPR_k_ChargeStatus.VeADPR_k_ChargeStatus
            OUT_VeADPR_b_ChargeReq_VeADPR_b_ChargeReq: accessed-variable=VeADPR_b_ChargeReq.VeADPR_b_ChargeReq
            OUT_VeADPR_I_ChrgCurrentRq_VeADPR_I_ChrgCurrentRq: accessed-variable=VeADPR_I_ChrgCurrentRq.VeADPR_I_ChrgCurrentRq
            OUT_VeADPR_U_ChrgVoltSetPt_VeADPR_U_ChrgVoltSetPt: accessed-variable=VeADPR_U_ChrgVoltSetPt.VeADPR_U_ChrgVoltSetPt
            OUT_VeADPR_k_DCRelayCheckReq_VeADPR_k_DCRelayCheckReq: accessed-variable=VeADPR_k_DCRelayCheckReq.VeADPR_k_DCRelayCheckReq
            OUT_VeADPR_b_ChgPlugInCounterReset_VeADPR_b_C_ad4d6c414c665a3c: accessed-variable=VeADPR_b_ChgPlugInCounterReset.VeADPR_b_ChgPlugInCounterReset
            OUT_VeADPR_k_ChargeMode_VeADPR_k_ChargeMode: accessed-variable=VeADPR_k_ChargeMode.VeADPR_k_ChargeMode
            OUT_VeADPR_k_OBCWorkingCommand_VeADPR_k_OBCWorkingCommand: accessed-variable=VeADPR_k_OBCWorkingCommand.VeADPR_k_OBCWorkingCommand
            OUT_VeADPR_k_OBCChDischReady_VeADPR_k_OBCChDischReady: accessed-variable=VeADPR_k_OBCChDischReady.VeADPR_k_OBCChDischReady
            OUT_VeADPR_k_BattNeedCharge_VeADPR_k_BattNeedCharge: accessed-variable=VeADPR_k_BattNeedCharge.VeADPR_k_BattNeedCharge
            OUT_VeADPR_b_ACOrDCChargeFullFlag_VeADPR_b_AC_0528c0c0296f2ece: accessed-variable=VeADPR_b_ACOrDCChargeFullFlag.VeADPR_b_ACOrDCChargeFullFlag
            OUT_VeADPR_b_AuxilPwrSply_VeADPR_b_AuxilPwrSply: accessed-variable=VeADPR_b_AuxilPwrSply.VeADPR_b_AuxilPwrSply
            OUT_VeADPR_b_CC2ConnState_VeADPR_b_CC2ConnState: accessed-variable=VeADPR_b_CC2ConnState.VeADPR_b_CC2ConnState
            OUT_VeADPR_T_FastChrgNegSocketTemp_VeADPR_T_F_be75d5710766164d: accessed-variable=VeADPR_T_FastChrgNegSocketTemp.VeADPR_T_FastChrgNegSocketTemp
            OUT_VeADPR_T_FastChrgPosSocketTemp_VeADPR_T_F_ccc610b54eae5a87: accessed-variable=VeADPR_T_FastChrgPosSocketTemp.VeADPR_T_FastChrgPosSocketTemp
            OUT_VeADPR_b_FCSocketTempSensorPos_Invalid_Ve_f6e0e391029de095: accessed-variable=VeADPR_b_FCSocketTempSensorPos_Invalid.VeADPR_b_FCSocketTempSensorPos_Invalid
            OUT_VeADPR_b_FCSocketTempSensorNeg_Invalid_Ve_cdeb2ce6c387fd2a: accessed-variable=VeADPR_b_FCSocketTempSensorNeg_Invalid.VeADPR_b_FCSocketTempSensorNeg_Invalid
            OUT_VeADPR_b_ChargeEn_VeADPR_b_ChargeEn: accessed-variable=VeADPR_b_ChargeEn.VeADPR_b_ChargeEn
            OUT_VeADPR_b_DCRelayStatus_VeADPR_b_DCRelayStatus: accessed-variable=VeADPR_b_DCRelayStatus.VeADPR_b_DCRelayStatus
            OUT_VeADPR_k_ShutDownReq_VeADPR_k_ShutDownReq: accessed-variable=VeADPR_k_ShutDownReq.VeADPR_k_ShutDownReq
            OUT_VeADPR_k_ChDIschWaitTimeOut_VeADPR_k_ChDIschWaitTimeOut: accessed-variable=VeADPR_k_ChDIschWaitTimeOut.VeADPR_k_ChDIschWaitTimeOut
            OUT_VeADPR_k_ChargeDischReady_VeADPR_k_ChargeDischReady: accessed-variable=VeADPR_k_ChargeDischReady.VeADPR_k_ChargeDischReady
            OUT_VeADPR_k_HeatingMethod_VeADPR_k_HeatingMethod: accessed-variable=VeADPR_k_HeatingMethod.VeADPR_k_HeatingMethod
            OUT_VeADPR_k_SendChargingStatus_VeADPR_k_SendChargingStatus: accessed-variable=VeADPR_k_SendChargingStatus.VeADPR_k_SendChargingStatus
            OUT_VeADPR_k_VehicleDischargingStatus_VeADPR_b95aa00b49aabac9: accessed-variable=VeADPR_k_VehicleDischargingStatus.VeADPR_k_VehicleDischargingStatus
            OUT_VeADPR_b_BattHeatChkComplt_VeADPR_b_BattHeatChkComplt: accessed-variable=VeADPR_b_BattHeatChkComplt.VeADPR_b_BattHeatChkComplt
            OUT_VeADPR_k_BattPreHeatReq_VeADPR_k_BattPreHeatReq: accessed-variable=VeADPR_k_BattPreHeatReq.VeADPR_k_BattPreHeatReq
            OUT_VeADPR_b_ReChDischargeReq_VeADPR_b_ReChDischargeReq: accessed-variable=VeADPR_b_ReChDischargeReq.VeADPR_b_ReChDischargeReq
            OUT_VeADPR_b_ACChConnect_VeADPR_b_ACChConnect: accessed-variable=VeADPR_b_ACChConnect.VeADPR_b_ACChConnect
            OUT_VeADPR_b_DisStopFlag_VeADPR_b_DisStopFlag: accessed-variable=VeADPR_b_DisStopFlag.VeADPR_b_DisStopFlag
            OUT_VeADPR_b_ChrgElecLock_VeADPR_b_ChrgElecLock: accessed-variable=VeADPR_b_ChrgElecLock.VeADPR_b_ChrgElecLock
            OUT_VeADPR_I_ChrgMaxOutCurr_VeADPR_I_ChrgMaxOutCurr: accessed-variable=VeADPR_I_ChrgMaxOutCurr.VeADPR_I_ChrgMaxOutCurr
            OUT_VeADPR_b_ACpreheatingEn_VeADPR_b_ACpreheatingEn: accessed-variable=VeADPR_b_ACpreheatingEn.VeADPR_b_ACpreheatingEn
            OUT_VeADPR_k_S2Command_VeADPR_k_S2Command: accessed-variable=VeADPR_k_S2Command.VeADPR_k_S2Command
            OUT_VeADPR_b_PosandNegClosed_VeADPR_b_PosandNegClosed: accessed-variable=VeADPR_b_PosandNegClosed.VeADPR_b_PosandNegClosed
            OUT_VeADPR_b_KeepWarmEn_VeADPR_b_KeepWarmEn: accessed-variable=VeADPR_b_KeepWarmEn.VeADPR_b_KeepWarmEn
            OUT_VeADPR_b_ACChargeSystemFault_VeADPR_b_ACChargeSystemFault: accessed-variable=VeADPR_b_ACChargeSystemFault.VeADPR_b_ACChargeSystemFault
            OUT_VeADPR_b_ShutDownEn_VeADPR_b_ShutDownEn: accessed-variable=VeADPR_b_ShutDownEn.VeADPR_b_ShutDownEn
            OUT_VeADPR_b_DCRelayStatusfault_VeADPR_b_DCRelayStatusfault: accessed-variable=VeADPR_b_DCRelayStatusfault.VeADPR_b_DCRelayStatusfault
            OUT_VeADPR_T_SlowChrgPosSocketTemp_VeADPR_T_S_5217c5c2dcf0e641: accessed-variable=VeADPR_T_SlowChrgPosSocketTemp.VeADPR_T_SlowChrgPosSocketTemp
            OUT_VeADPR_T_SlowChrgNegSocketTemp_VeADPR_T_S_1d5ee1f626fc76c0: accessed-variable=VeADPR_T_SlowChrgNegSocketTemp.VeADPR_T_SlowChrgNegSocketTemp
            OUT_VeADPR_b_FastChrgSocketTempDetectEn_VeADP_5062c4fdc5d3c566: accessed-variable=VeADPR_b_FastChrgSocketTempDetectEn.VeADPR_b_FastChrgSocketTempDetectEn
            OUT_VeADPR_b_ECCFucLimitCMD_VeADPR_b_ECCFucLimitCMD: accessed-variable=VeADPR_b_ECCFucLimitCMD.VeADPR_b_ECCFucLimitCMD
            OUT_VeADPR_k_BookSetReq_VeADPR_k_BookSetReq: accessed-variable=VeADPR_k_BookSetReq.VeADPR_k_BookSetReq
            OUT_VeADPR_k_IntelligentChargeReq_VeADPR_k_In_7bfd18d47cf846ba: accessed-variable=VeADPR_k_IntelligentChargeReq.VeADPR_k_IntelligentChargeReq
            OUT_VeADPR_k_BatteryMaintainLightReq_VeADPR_k_fe70eb47f5ac9770: accessed-variable=VeADPR_k_BatteryMaintainLightReq.VeADPR_k_BatteryMaintainLightReq
            OUT_VeADPR_k_ChargeOutMinCurSet_VeADPR_k_ChargeOutMinCurSet: accessed-variable=VeADPR_k_ChargeOutMinCurSet.VeADPR_k_ChargeOutMinCurSet
            OUT_VeADPR_b_ACPConnect_VeADPR_b_ACPConnect: accessed-variable=VeADPR_b_ACPConnect.VeADPR_b_ACPConnect
        112 x parameter access:
          CALPRM_ADPR_Rport_KeADPR_I_ChrgCurrentRqOvrdVal: accessed-parameter=ADPR_Rport.KeADPR_I_ChrgCurrentRqOvrdVal
          CALPRM_ADPR_Rport_KeADPR_I_ChrgMaxOutCurrOvrdVal: accessed-parameter=ADPR_Rport.KeADPR_I_ChrgMaxOutCurrOvrdVal
          CALPRM_ADPR_Rport_KeADPR_I_OBCMaxOutPowOvrdVal: accessed-parameter=ADPR_Rport.KeADPR_I_OBCMaxOutPowOvrdVal
          CALPRM_ADPR_Rport_KeADPR_I_PreheatingCurrentRq: accessed-parameter=ADPR_Rport.KeADPR_I_PreheatingCurrentRq
          CALPRM_ADPR_Rport_KeADPR_T_MaxTAllowToHeat: accessed-parameter=ADPR_Rport.KeADPR_T_MaxTAllowToHeat
          CALPRM_ADPR_Rport_KeADPR_T_MinTAllowToChrg: accessed-parameter=ADPR_Rport.KeADPR_T_MinTAllowToChrg
          CALPRM_ADPR_Rport_KeADPR_U_ChrgVoltSetPtOvrdVal: accessed-parameter=ADPR_Rport.KeADPR_U_ChrgVoltSetPtOvrdVal
          CALPRM_ADPR_Rport_KeADPR_U_OBCInputVoltageMax: accessed-parameter=ADPR_Rport.KeADPR_U_OBCInputVoltageMax
          CALPRM_ADPR_Rport_KeADPR_U_OBCInputVoltageMin: accessed-parameter=ADPR_Rport.KeADPR_U_OBCInputVoltageMin
          CALPRM_ADPR_Rport_KeADPR_b_ACChargeSystemFaultEn: accessed-parameter=ADPR_Rport.KeADPR_b_ACChargeSystemFaultEn
          CALPRM_ADPR_Rport_KeADPR_b_ACChargeSystemFaultVal: accessed-parameter=ADPR_Rport.KeADPR_b_ACChargeSystemFaultVal
          CALPRM_ADPR_Rport_KeADPR_b_ACOrDCChargeFullFlagEn: accessed-parameter=ADPR_Rport.KeADPR_b_ACOrDCChargeFullFlagEn
          CALPRM_ADPR_Rport_KeADPR_b_ACOrDCChargeFullFlagOvrdVal: accessed-parameter=ADPR_Rport.KeADPR_b_ACOrDCChargeFullFlagOvrdVal
          CALPRM_ADPR_Rport_KeADPR_b_BattHeatChkCompltOvrdEn: accessed-parameter=ADPR_Rport.KeADPR_b_BattHeatChkCompltOvrdEn
          CALPRM_ADPR_Rport_KeADPR_b_BattHeatChkCompltOvrdVal: accessed-parameter=ADPR_Rport.KeADPR_b_BattHeatChkCompltOvrdVal
          CALPRM_ADPR_Rport_KeADPR_b_BattPreHeatReqOvrdEn: accessed-parameter=ADPR_Rport.KeADPR_b_BattPreHeatReqOvrdEn
          CALPRM_ADPR_Rport_KeADPR_b_CCOvrdEn: accessed-parameter=ADPR_Rport.KeADPR_b_CCOvrdEn
          CALPRM_ADPR_Rport_KeADPR_b_CCOvrdVal: accessed-parameter=ADPR_Rport.KeADPR_b_CCOvrdVal
          CALPRM_ADPR_Rport_KeADPR_b_CPOvrdEn: accessed-parameter=ADPR_Rport.KeADPR_b_CPOvrdEn
          CALPRM_ADPR_Rport_KeADPR_b_CPOvrdVal: accessed-parameter=ADPR_Rport.KeADPR_b_CPOvrdVal
          CALPRM_ADPR_Rport_KeADPR_b_ChDIschWaitTimeOutOvrdEn: accessed-parameter=ADPR_Rport.KeADPR_b_ChDIschWaitTimeOutOvrdEn
          CALPRM_ADPR_Rport_KeADPR_b_ChargeDischReadyOvrdEn: accessed-parameter=ADPR_Rport.KeADPR_b_ChargeDischReadyOvrdEn
          CALPRM_ADPR_Rport_KeADPR_b_ChargeReqOvrdEn: accessed-parameter=ADPR_Rport.KeADPR_b_ChargeReqOvrdEn
          CALPRM_ADPR_Rport_KeADPR_b_ChargeReqOvrdVal: accessed-parameter=ADPR_Rport.KeADPR_b_ChargeReqOvrdVal
          CALPRM_ADPR_Rport_KeADPR_b_ChargeStatusOvrdEn: accessed-parameter=ADPR_Rport.KeADPR_b_ChargeStatusOvrdEn
          CALPRM_ADPR_Rport_KeADPR_b_ChrgCurrentRqOvrdEn: accessed-parameter=ADPR_Rport.KeADPR_b_ChrgCurrentRqOvrdEn
          CALPRM_ADPR_Rport_KeADPR_b_ChrgElecLockOvrdEn: accessed-parameter=ADPR_Rport.KeADPR_b_ChrgElecLockOvrdEn
          CALPRM_ADPR_Rport_KeADPR_b_ChrgElecLockOvrdVal: accessed-parameter=ADPR_Rport.KeADPR_b_ChrgElecLockOvrdVal
          CALPRM_ADPR_Rport_KeADPR_b_ChrgMaxOutCurrOvrdEn: accessed-parameter=ADPR_Rport.KeADPR_b_ChrgMaxOutCurrOvrdEn
          CALPRM_ADPR_Rport_KeADPR_b_ChrgVoltSetPtOvrdEn: accessed-parameter=ADPR_Rport.KeADPR_b_ChrgVoltSetPtOvrdEn
          CALPRM_ADPR_Rport_KeADPR_b_DCRelayCheckReqOvrdEn: accessed-parameter=ADPR_Rport.KeADPR_b_DCRelayCheckReqOvrdEn
          CALPRM_ADPR_Rport_KeADPR_b_DCRelayStatusfaultEn: accessed-parameter=ADPR_Rport.KeADPR_b_DCRelayStatusfaultEn
          CALPRM_ADPR_Rport_KeADPR_b_DCRelayStatusfaultVal: accessed-parameter=ADPR_Rport.KeADPR_b_DCRelayStatusfaultVal
          CALPRM_ADPR_Rport_KeADPR_b_DisStopFlagOvrdEn: accessed-parameter=ADPR_Rport.KeADPR_b_DisStopFlagOvrdEn
          CALPRM_ADPR_Rport_KeADPR_b_DisStopFlagOvrdVal: accessed-parameter=ADPR_Rport.KeADPR_b_DisStopFlagOvrdVal
          CALPRM_ADPR_Rport_KeADPR_b_FastChrgSocketTempDetectEn: accessed-parameter=ADPR_Rport.KeADPR_b_FastChrgSocketTempDetectEn
          CALPRM_ADPR_Rport_KeADPR_b_FastChrgSocketTempDetectVal: accessed-parameter=ADPR_Rport.KeADPR_b_FastChrgSocketTempDetectVal
          CALPRM_ADPR_Rport_KeADPR_b_HeatingMethodOvrdEn: accessed-parameter=ADPR_Rport.KeADPR_b_HeatingMethodOvrdEn
          CALPRM_ADPR_Rport_KeADPR_b_KeepWarmEn: accessed-parameter=ADPR_Rport.KeADPR_b_KeepWarmEn
          CALPRM_ADPR_Rport_KeADPR_b_KeepWarmVal: accessed-parameter=ADPR_Rport.KeADPR_b_KeepWarmVal
          CALPRM_ADPR_Rport_KeADPR_b_OBCMaxOutPowOvrdEn: accessed-parameter=ADPR_Rport.KeADPR_b_OBCMaxOutPowOvrdEn
          CALPRM_ADPR_Rport_KeADPR_b_PosAndNegClosedEn: accessed-parameter=ADPR_Rport.KeADPR_b_PosAndNegClosedEn
          CALPRM_ADPR_Rport_KeADPR_b_PosAndNegClosedVal: accessed-parameter=ADPR_Rport.KeADPR_b_PosAndNegClosedVal
          CALPRM_ADPR_Rport_KeADPR_b_ReChDischargeReqOvrdEn: accessed-parameter=ADPR_Rport.KeADPR_b_ReChDischargeReqOvrdEn
          CALPRM_ADPR_Rport_KeADPR_b_S2CommandOvrdEn: accessed-parameter=ADPR_Rport.KeADPR_b_S2CommandOvrdEn
          CALPRM_ADPR_Rport_KeADPR_b_SendChargingStatusOvrdEn: accessed-parameter=ADPR_Rport.KeADPR_b_SendChargingStatusOvrdEn
          CALPRM_ADPR_Rport_KeADPR_b_ShutDownEn: accessed-parameter=ADPR_Rport.KeADPR_b_ShutDownEn
          CALPRM_ADPR_Rport_KeADPR_b_ShutDownReqOvrdEn: accessed-parameter=ADPR_Rport.KeADPR_b_ShutDownReqOvrdEn
          CALPRM_ADPR_Rport_KeADPR_b_ShutDownVal: accessed-parameter=ADPR_Rport.KeADPR_b_ShutDownVal
          CALPRM_ADPR_Rport_KeADPR_b_SlowChrgNegSocketTempEn: accessed-parameter=ADPR_Rport.KeADPR_b_SlowChrgNegSocketTempEn
          CALPRM_ADPR_Rport_KeADPR_b_SlowChrgNegSocketTempVal: accessed-parameter=ADPR_Rport.KeADPR_b_SlowChrgNegSocketTempVal
          CALPRM_ADPR_Rport_KeADPR_b_SlowChrgPosSocketTempEn: accessed-parameter=ADPR_Rport.KeADPR_b_SlowChrgPosSocketTempEn
          CALPRM_ADPR_Rport_KeADPR_b_SlowChrgPosSocketTempVal: accessed-parameter=ADPR_Rport.KeADPR_b_SlowChrgPosSocketTempVal
          CALPRM_ADPR_Rport_KeADPR_b_TempLoEnable: accessed-parameter=ADPR_Rport.KeADPR_b_TempLoEnable
          CALPRM_ADPR_Rport_KeADPR_b_TempLoOvrd: accessed-parameter=ADPR_Rport.KeADPR_b_TempLoOvrd
          CALPRM_ADPR_Rport_KeADPR_b_VehicleDischargingStatusOvrdEn: accessed-parameter=ADPR_Rport.KeADPR_b_VehicleDischargingStatusOvrdEn
          CALPRM_ADPR_Rport_KeADPR_k_BattPreHeatReqOvrdVal: accessed-parameter=ADPR_Rport.KeADPR_k_BattPreHeatReqOvrdVal
          CALPRM_ADPR_Rport_KeADPR_k_ChDIschWaitTimeOutOvrdVal: accessed-parameter=ADPR_Rport.KeADPR_k_ChDIschWaitTimeOutOvrdVal
          CALPRM_ADPR_Rport_KeADPR_k_ChargeDischReadyOvrdVal: accessed-parameter=ADPR_Rport.KeADPR_k_ChargeDischReadyOvrdVal
          CALPRM_ADPR_Rport_KeADPR_k_ChargeStatusOvrdVal: accessed-parameter=ADPR_Rport.KeADPR_k_ChargeStatusOvrdVal
          CALPRM_ADPR_Rport_KeADPR_k_DCRelayCheckReqOvrdVal: accessed-parameter=ADPR_Rport.KeADPR_k_DCRelayCheckReqOvrdVal
          CALPRM_ADPR_Rport_KeADPR_k_HeatingMethodOvrdVal: accessed-parameter=ADPR_Rport.KeADPR_k_HeatingMethodOvrdVal
          CALPRM_ADPR_Rport_KeADPR_k_ReChDischargeReqOvrdVal: accessed-parameter=ADPR_Rport.KeADPR_k_ReChDischargeReqOvrdVal
          CALPRM_ADPR_Rport_KeADPR_k_S2CommandOvrdVal: accessed-parameter=ADPR_Rport.KeADPR_k_S2CommandOvrdVal
          CALPRM_ADPR_Rport_KeADPR_k_SendChargingStatusOvrdVal: accessed-parameter=ADPR_Rport.KeADPR_k_SendChargingStatusOvrdVal
          CALPRM_ADPR_Rport_KeADPR_k_ShutDownReqOvrdVal: accessed-parameter=ADPR_Rport.KeADPR_k_ShutDownReqOvrdVal
          CALPRM_ADPR_Rport_KeADPR_k_VehicleDischargingStatusOvrdVal: accessed-parameter=ADPR_Rport.KeADPR_k_VehicleDischargingStatusOvrdVal
          CALPRM_ADPR_Rport_KeADPR_t_ACChargeNoConnect_Timer: accessed-parameter=ADPR_Rport.KeADPR_t_ACChargeNoConnect_Timer
          CALPRM_ADPR_Rport_KeADPR_t_ACChargeNoConnect_Timer1: accessed-parameter=ADPR_Rport.KeADPR_t_ACChargeNoConnect_Timer1
          CALPRM_ADPR_Rport_KeADPR_t_ACChargeSemiConnect_Timer: accessed-parameter=ADPR_Rport.KeADPR_t_ACChargeSemiConnect_Timer
          CALPRM_ADPR_Rport_KeADPR_t_ACChargeSemiConnect_Timer1: accessed-parameter=ADPR_Rport.KeADPR_t_ACChargeSemiConnect_Timer1
          CALPRM_ADPR_Rport_KeADPR_t_ACVoltageExceed_Timer: accessed-parameter=ADPR_Rport.KeADPR_t_ACVoltageExceed_Timer
          CALPRM_ADPR_Rport_KeADPR_t_BattPowerOffThresh{1..3}: accessed-parameter=ADPR_Rport.KeADPR_t_BattPowerOffThresh{1..3}
          CALPRM_ADPR_Rport_KeADPR_t_CHMR_FunctionCallRate: accessed-parameter=ADPR_Rport.KeADPR_t_CHMR_FunctionCallRate
          CALPRM_ADPR_Rport_KeADPR_t_ChrgEnDelay: accessed-parameter=ADPR_Rport.KeADPR_t_ChrgEnDelay
          CALPRM_ADPR_Rport_KeADPR_t_DCRelayCheckReqReSetTime: accessed-parameter=ADPR_Rport.KeADPR_t_DCRelayCheckReqReSetTime
          CALPRM_ADPR_Rport_KeADPR_t_DCRelayCheckReqSetTime: accessed-parameter=ADPR_Rport.KeADPR_t_DCRelayCheckReqSetTime
          CALPRM_ADPR_Rport_KeADPR_t_DCRelayStatusfault_Timer: accessed-parameter=ADPR_Rport.KeADPR_t_DCRelayStatusfault_Timer
          CALPRM_ADPR_Rport_KeADPR_t_DiscButtonPress_Timer1: accessed-parameter=ADPR_Rport.KeADPR_t_DiscButtonPress_Timer1
          CALPRM_ADPR_Rport_KeADPR_t_DiscManualStop_Timer1: accessed-parameter=ADPR_Rport.KeADPR_t_DiscManualStop_Timer1
          CALPRM_ADPR_Rport_KeADPR_t_DiscVehicleStatus_Timer1: accessed-parameter=ADPR_Rport.KeADPR_t_DiscVehicleStatus_Timer1
          CALPRM_ADPR_Rport_KeADPR_t_ElecLockUnlocking_Timer: accessed-parameter=ADPR_Rport.KeADPR_t_ElecLockUnlocking_Timer
          CALPRM_ADPR_Rport_KeADPR_t_FunctionCallRate: accessed-parameter=ADPR_Rport.KeADPR_t_FunctionCallRate
          CALPRM_ADPR_Rport_KeADPR_t_NoRequireShutDownReset: accessed-parameter=ADPR_Rport.KeADPR_t_NoRequireShutDownReset
          CALPRM_ADPR_Rport_KeADPR_t_NoRequireShutDownSet: accessed-parameter=ADPR_Rport.KeADPR_t_NoRequireShutDownSet
          CALPRM_ADPR_Rport_KeADPR_t_OBCFltStatus_Timer: accessed-parameter=ADPR_Rport.KeADPR_t_OBCFltStatus_Timer
          CALPRM_ADPR_Rport_KeADPR_t_OBCFltStatus_Timer1: accessed-parameter=ADPR_Rport.KeADPR_t_OBCFltStatus_Timer1
          CALPRM_ADPR_Rport_KeADPR_t_OBCInputVoltageUnnormal_Timer1: accessed-parameter=ADPR_Rport.KeADPR_t_OBCInputVoltageUnnormal_Timer1
          CALPRM_ADPR_Rport_KeADPR_t_OBCNoVTOLMode_Timer1: accessed-parameter=ADPR_Rport.KeADPR_t_OBCNoVTOLMode_Timer1
          CALPRM_ADPR_Rport_KeADPR_t_OBCNoVTOVMode_Timer1: accessed-parameter=ADPR_Rport.KeADPR_t_OBCNoVTOVMode_Timer1
          CALPRM_ADPR_Rport_KeADPR_t_OBCNochargingMode_Timer: accessed-parameter=ADPR_Rport.KeADPR_t_OBCNochargingMode_Timer
          CALPRM_ADPR_Rport_KeADPR_t_OBCNochargingMode_Timer1: accessed-parameter=ADPR_Rport.KeADPR_t_OBCNochargingMode_Timer1
          CALPRM_ADPR_Rport_KeADPR_t_OBCStandbyModelMismatchFlt_Timer: accessed-parameter=ADPR_Rport.KeADPR_t_OBCStandbyModelMismatchFlt_Timer
          CALPRM_ADPR_Rport_KeADPR_t_OBCUnnormalStatus_Timer1: accessed-parameter=ADPR_Rport.KeADPR_t_OBCUnnormalStatus_Timer1
          CALPRM_ADPR_Rport_KeADPR_t_OBCWorkingModelMismatchFlt_Timer: accessed-parameter=ADPR_Rport.KeADPR_t_OBCWorkingModelMismatchFlt_Timer
          CALPRM_ADPR_Rport_KeADPR_t_PowerSupplyStatus2_Timer: accessed-parameter=ADPR_Rport.KeADPR_t_PowerSupplyStatus2_Timer
          CALPRM_ADPR_Rport_KeADPR_t_PowerSupplyStatus3_Timer1: accessed-parameter=ADPR_Rport.KeADPR_t_PowerSupplyStatus3_Timer1
          CALPRM_ADPR_Rport_KeADPR_t_S2CommandWaiting: accessed-parameter=ADPR_Rport.KeADPR_t_S2CommandWaiting
          CALPRM_ADPR_Rport_KeADPR_t_VTOLOBCNoVTOLMode_Timer1: accessed-parameter=ADPR_Rport.KeADPR_t_VTOLOBCNoVTOLMode_Timer1
          CALPRM_ADPR_Rport_KeADPR_t_VTOVACChargeNoConnect_Timer: accessed-parameter=ADPR_Rport.KeADPR_t_VTOVACChargeNoConnect_Timer
          CALPRM_ADPR_Rport_KeADPR_t_VTOVACChargeSemiConnect_Timer: accessed-parameter=ADPR_Rport.KeADPR_t_VTOVACChargeSemiConnect_Timer
          CALPRM_ADPR_Rport_KeADPR_t_VTOVDiscButtonPress_Timer1: accessed-parameter=ADPR_Rport.KeADPR_t_VTOVDiscButtonPress_Timer1
          CALPRM_ADPR_Rport_KeADPR_t_VTOVDiscManualStop_Timer1: accessed-parameter=ADPR_Rport.KeADPR_t_VTOVDiscManualStop_Timer1
          CALPRM_ADPR_Rport_KeADPR_t_VTOVDiscVehicleStatus_Timer1: accessed-parameter=ADPR_Rport.KeADPR_t_VTOVDiscVehicleStatus_Timer1
          CALPRM_ADPR_Rport_KeADPR_t_VTOVElecLockUnlocking_Timer: accessed-parameter=ADPR_Rport.KeADPR_t_VTOVElecLockUnlocking_Timer
          CALPRM_ADPR_Rport_KeADPR_t_VTOVOBCFltStatus_Timer1: accessed-parameter=ADPR_Rport.KeADPR_t_VTOVOBCFltStatus_Timer1
          CALPRM_ADPR_Rport_KeADPR_t_VTOVOBCNoVTOVMode_Timer1: accessed-parameter=ADPR_Rport.KeADPR_t_VTOVOBCNoVTOVMode_Timer1
          CALPRM_ADPR_Rport_KeADPR_t_VTOVOBCWorkingMode_c511fc359e4b14a6: accessed-parameter=ADPR_Rport.KeADPR_t_VTOVOBCWorkingModelMismatchFlt1_Timer
          CALPRM_ADPR_Rport_KeADPR_t_VTOVOBCWorkingMode_bd4dbb37ce76b60f: accessed-parameter=ADPR_Rport.KeADPR_t_VTOVOBCWorkingModelMismatchFlt_Timer
          CALPRM_ADPR_Rport_KeADPR_t_VehicleStateWaiting_Timer1: accessed-parameter=ADPR_Rport.KeADPR_t_VehicleStateWaiting_Timer1
package /CalibrationComponents
  parameter sw component type ADPR: data-type-mapping=ADPR_CodeDataTypeMappingsSet
    provide port ADPR_Pport: provided-interface=ADPR_if
      provided-com-specs:
        init-value=0, parameter=KeADPR_I_ChrgCurrentRqOvrdVal
        init-value=0, parameter=KeADPR_I_OBCMaxOutPowOvrdVal
        init-value=3, parameter=KeADPR_I_PreheatingCurrentRq
        init-value=10, parameter=KeADPR_T_MaxTAllowToHeat
        init-value=5, parameter=KeADPR_T_MinTAllowToChrg
        init-value=0, parameter=KeADPR_U_ChrgVoltSetPtOvrdVal
        init-value=275, parameter=KeADPR_U_OBCInputVoltageMax
        init-value=85, parameter=KeADPR_U_OBCInputVoltageMin
        init-value=0, parameter=KeADPR_b_SlowChrgNegSocketTempVal
        init-value=0, parameter=KeADPR_b_SlowChrgPosSocketTempVal
        init-value=0.30000001192092896, parameter=KeADPR_t_ACChargeNoConnect_Timer
        init-value=0.30000001192092896, parameter=KeADPR_t_ACChargeNoConnect_Timer1
        init-value=180, parameter=KeADPR_t_ACChargeSemiConnect_Timer
        init-value=600, parameter=KeADPR_t_ACChargeSemiConnect_Timer1
        init-value=10, parameter=KeADPR_t_ACVoltageExceed_Timer
        init-value=0.019999999552965164, parameter=KeADPR_t_BattPowerOffThresh1
        init-value=30, parameter=KeADPR_t_BattPowerOffThresh2
        init-value=600, parameter=KeADPR_t_BattPowerOffThresh3
        init-value=0.009999999776482582, parameter=KeADPR_t_CHMR_FunctionCallRate
        init-value=1, parameter=KeADPR_t_ChrgEnDelay
        init-value=0.019999999552965164, parameter=KeADPR_t_DCRelayCheckReqReSetTime
        init-value=0, parameter=KeADPR_t_DCRelayCheckReqSetTime
        init-value=0.019999999552965164, parameter=KeADPR_t_DCRelayStatusfault_Timer
        init-value=600, parameter=KeADPR_t_DiscButtonPress_Timer1
        init-value=0.30000001192092896, parameter=KeADPR_t_DiscManualStop_Timer1
        init-value=600, parameter=KeADPR_t_DiscVehicleStatus_Timer1
        init-value=180, parameter=KeADPR_t_ElecLockUnlocking_Timer
        init-value=0.009999999776482582, parameter=KeADPR_t_FunctionCallRate
        init-value=0, parameter=KeADPR_t_NoRequireShutDownReset
        init-value=1.100000023841858, parameter=KeADPR_t_NoRequireShutDownSet
        init-value=1, parameter=KeADPR_t_OBCFltStatus_Timer
        init-value=600, parameter=KeADPR_t_OBCFltStatus_Timer1
        init-value=600, parameter=KeADPR_t_OBCInputVoltageUnnormal_Timer1
        init-value=600, parameter=KeADPR_t_OBCNoVTOLMode_Timer1
        init-value=600, parameter=KeADPR_t_OBCNoVTOVMode_Timer1
        init-value=180, parameter=KeADPR_t_OBCNochargingMode_Timer
        init-value=600, parameter=KeADPR_t_OBCNochargingMode_Timer1
        init-value=180, parameter=KeADPR_t_OBCStandbyModelMismatchFlt_Timer
        init-value=600, parameter=KeADPR_t_OBCUnnormalStatus_Timer1
        init-value=180, parameter=KeADPR_t_OBCWorkingModelMismatchFlt_Timer
        init-value=180, parameter=KeADPR_t_PowerSupplyStatus2_Timer
        init-value=600, parameter=KeADPR_t_PowerSupplyStatus3_Timer1
        init-value=0.30000001192092896, parameter=KeADPR_t_S2CommandWaiting
        init-value=180, parameter=KeADPR_t_VTOLOBCNoVTOLMode_Timer1
        init-value=0.30000001192092896, parameter=KeADPR_t_VTOVACChargeNoConnect_Timer
        init-value=180, parameter=KeADPR_t_VTOVACChargeSemiConnect_Timer
        init-value=180, parameter=KeADPR_t_VTOVDiscButtonPress_Timer1
        init-value=0.30000001192092896, parameter=KeADPR_t_VTOVDiscManualStop_Timer1
        init-value=180, parameter=KeADPR_t_VTOVDiscVehicleStatus_Timer1
        init-value=180, parameter=KeADPR_t_VTOVElecLockUnlocking_Timer
        init-value=0.30000001192092896, parameter=KeADPR_t_VTOVOBCFltStatus_Timer1
        init-value=180, parameter=KeADPR_t_VTOVOBCNoVTOVMode_Timer1
        init-value=180, parameter=KeADPR_t_VTOVOBCWorkingModelMismatchFlt1_Timer
        init-value=180, parameter=KeADPR_t_VTOVOBCWorkingModelMismatchFlt_Timer
        init-value=900, parameter=KeADPR_t_VehicleStateWaiting_Timer1
        init-value=0, parameter=KeADPR_b_ACChargeSystemFaultEn
        init-value=0, parameter=KeADPR_b_ACChargeSystemFaultVal
        init-value=0, parameter=KeADPR_b_ACOrDCChargeFullFlagEn
        init-value=0, parameter=KeADPR_b_ACOrDCChargeFullFlagOvrdVal
        init-value=0, parameter=KeADPR_b_BattHeatChkCompltOvrdEn
        init-value=0, parameter=KeADPR_b_BattPreHeatReqOvrdEn
        init-value=0, parameter=KeADPR_b_CCOvrdEn
        init-value=0, parameter=KeADPR_b_CCOvrdVal
        init-value=0, parameter=KeADPR_b_CPOvrdEn
        init-value=0, parameter=KeADPR_b_CPOvrdVal
        init-value=0, parameter=KeADPR_b_ChDIschWaitTimeOutOvrdEn
        init-value=0, parameter=KeADPR_b_ChargeDischReadyOvrdEn
        init-value=0, parameter=KeADPR_b_ChargeReqOvrdEn
        init-value=0, parameter=KeADPR_b_ChargeReqOvrdVal
        init-value=0, parameter=KeADPR_b_ChargeStatusOvrdEn
        init-value=0, parameter=KeADPR_b_ChrgCurrentRqOvrdEn
        init-value=0, parameter=KeADPR_b_ChrgElecLockOvrdEn
        init-value=0, parameter=KeADPR_b_ChrgMaxOutCurrOvrdEn
        init-value=0, parameter=KeADPR_b_ChrgVoltSetPtOvrdEn
        init-value=0, parameter=KeADPR_b_DCRelayCheckReqOvrdEn
        init-value=0, parameter=KeADPR_b_DCRelayStatusfaultEn
        init-value=0, parameter=KeADPR_b_DCRelayStatusfaultVal
        init-value=0, parameter=KeADPR_b_DisStopFlagOvrdEn
        init-value=0, parameter=KeADPR_b_FastChrgSocketTempDetectEn
        init-value=0, parameter=KeADPR_b_FastChrgSocketTempDetectVal
        init-value=0, parameter=KeADPR_b_HeatingMethodOvrdEn
        init-value=0, parameter=KeADPR_b_KeepWarmEn
        init-value=0, parameter=KeADPR_b_KeepWarmVal
        init-value=0, parameter=KeADPR_b_OBCMaxOutPowOvrdEn
        init-value=0, parameter=KeADPR_b_PosAndNegClosedEn
        init-value=0, parameter=KeADPR_b_ReChDischargeReqOvrdEn
        init-value=0, parameter=KeADPR_b_S2CommandOvrdEn
        init-value=0, parameter=KeADPR_b_SendChargingStatusOvrdEn
        init-value=0, parameter=KeADPR_b_ShutDownEn
        init-value=0, parameter=KeADPR_b_ShutDownReqOvrdEn
        init-value=0, parameter=KeADPR_b_ShutDownVal
        init-value=0, parameter=KeADPR_b_SlowChrgNegSocketTempEn
        init-value=0, parameter=KeADPR_b_SlowChrgPosSocketTempEn
        init-value=0, parameter=KeADPR_b_TempLoEnable
        init-value=1, parameter=KeADPR_b_TempLoOvrd
        init-value=0, parameter=KeADPR_b_VehicleDischargingStatusOvrdEn
        init-value=0, parameter=KeADPR_I_ChrgMaxOutCurrOvrdVal
        init-value=0, parameter=KeADPR_b_BattHeatChkCompltOvrdVal
        init-value=0, parameter=KeADPR_b_ChrgElecLockOvrdVal
        init-value=0, parameter=KeADPR_b_DisStopFlagOvrdVal
        init-value=0, parameter=KeADPR_b_PosAndNegClosedVal
        init-value=0, parameter=KeADPR_k_BattPreHeatReqOvrdVal
        init-value=0, parameter=KeADPR_k_ChDIschWaitTimeOutOvrdVal
        init-value=0, parameter=KeADPR_k_ChargeDischReadyOvrdVal
        init-value=0, parameter=KeADPR_k_ChargeStatusOvrdVal
        init-value=0, parameter=KeADPR_k_DCRelayCheckReqOvrdVal
        init-value=0, parameter=KeADPR_k_HeatingMethodOvrdVal
        init-value=0, parameter=KeADPR_k_ReChDischargeReqOvrdVal
        init-value=0, parameter=KeADPR_k_S2CommandOvrdVal
        init-value=0, parameter=KeADPR_k_SendChargingStatusOvrdVal
        init-value=0, parameter=KeADPR_k_ShutDownReqOvrdVal
        init-value=0, parameter=KeADPR_k_VehicleDischargingStatusOvrdVal
